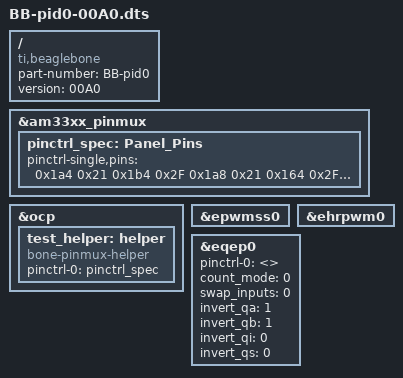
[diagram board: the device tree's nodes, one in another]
/dts-v1/;
/plugin/;


/ {
	compatible = "ti,beaglebone", "ti,beaglebone-black";
	part-number = "BB-pid0"; /* pin 9.22 */
	version = "00A0";
	fragment@0 {
		target = <&am33xx_pinmux>;
		__overlay__ {
			pinctrl_spec: Panel_Pins {
				pinctrl-single,pins = <
			/* P9_27_qep_pin: pinmux_P9_27_qep_pin */
				0x1a4  0x21	/* Mode 1, Pull-Down, RxActive */
			/* P9_41_gpio_pin: pinmux_P9_41_gpio_pin */
				0x1b4  0x2F /* Mode 7, RxActive */
			/* P9_91_qep_pin: pinmux_P9_91_qep_pin */
				0x1a8  0x21 /* Mode 1, Pull-Down, RxActive */
			/* P9_42_gpio_pin: pinmux_P9_42_gpio_pin */
				0x164  0x2F	/* Mode 7, RxActive */
			/* P9_92_qep_pin: pinmux_P9_92_qep_pin */
				0x1a0  0x21 /* Mode 1, Pull-Down, RxActive */
			/* P9_22 Mode3 ehrpwm0A PWM */
				0x150 0x33 
			/* P9_15_gpio_pin: pinmux_P9_15_gpio_pin */
				0x040  0x2F /* *will need to be configured outupt* Mode 7, RxActive */
			/* P9_16_gpio_pin: pinmux_P9_16_gpio_pin */
				0x04c  0x2F /* again, to be output. Mode 7, RxActive */
			>;
			}; 
		}
	};
	fragment@1 {
		target = <&ocp>;
		__overlay__ {
			test_helper: helper {
				compatible = "bone-pinmux-helper";
				pinctrl-names = "default";
				pinctrl-0 = <&pinctrl_spec>;
				status = "okay";
			};
		};
	};

	fragment@2 {
		target = <&epwmss0>;
		__overlay__ {
			status = "okay";
		};
	};


	fragment@3 {
		target = <&ehrpwm0>;
		__overlay__ {
			status = "okay";
		};
	};

	fragment@4 {
		target = <&eqep0>;
		__overlay__ {
					pinctrl-names = "default";
					pinctrl-0 = <>;

					count_mode = <0>;  /* 0 - Quadrature mode, normal 90 phase offset cha & chb.  1 - Direction mode.  cha input = clock, chb input = direction */
					swap_inputs = <0>; /* Are channel A and channel B swapped? (0 - no, 1 - yes) */
					invert_qa = <1>;   /* Should we invert the channel A input?  */
					invert_qb = <1>;   /* Should we invert the channel B input? I invert these because my encoder outputs drive transistors that pull down the pins */
					invert_qi = <0>;   /* Should we invert the index input? */
					invert_qs = <0>;   /* Should we invert the strobe input? */

			status = "okay";
		};
	};
};


